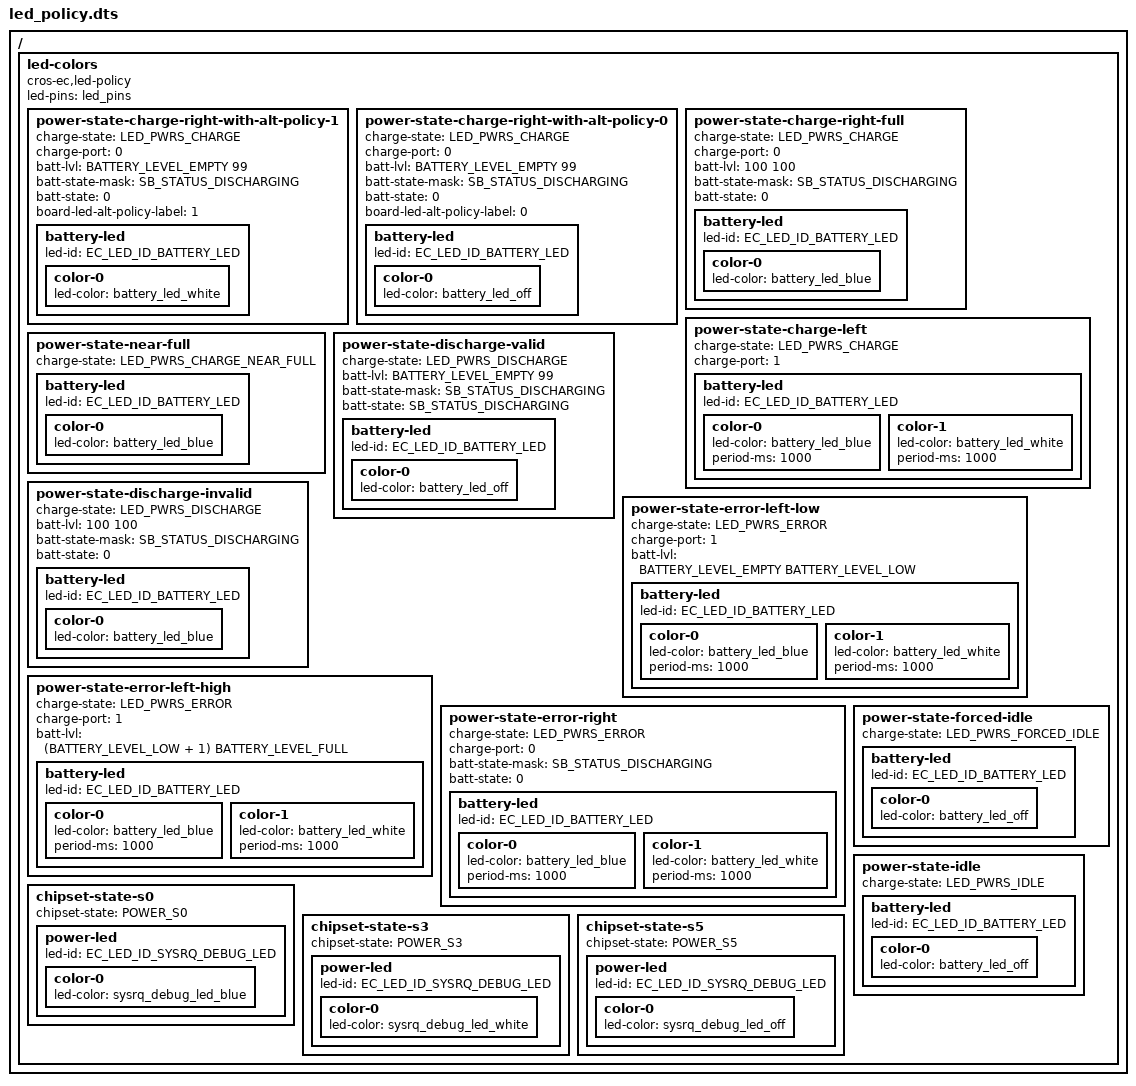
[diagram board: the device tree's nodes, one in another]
/* Copyright 2022 The ChromiumOS Authors
 * Use of this source code is governed by a BSD-style license that can be
 * found in the LICENSE file.
 */

/* Based off of `ec/zephyr/program/brox/led_policy.dtsi`
 * Modified led-colors to obtain better test coverage.
 */

#include <dt-bindings/battery.h>

/ {
	led-colors {
		compatible = "cros-ec,led-policy";
		led-pins = <&led_pins>;

		power-state-charge-right-with-alt-policy-1 {
			charge-state = "LED_PWRS_CHARGE";
			charge-port = <0>; /* Right port */
			batt-lvl = <BATTERY_LEVEL_EMPTY 99>;
			/* Battery is charging */
			batt-state-mask = <SB_STATUS_DISCHARGING>;
			batt-state = <0>;
			board-led-alt-policy-label = <1>;

			battery-led {
				led-id = "EC_LED_ID_BATTERY_LED";

				color-0 {
					led-color = <&battery_led_white>;
				};
			};
		};

		power-state-charge-right-with-alt-policy-0 {
			charge-state = "LED_PWRS_CHARGE";
			charge-port = <0>; /* Right port */
			batt-lvl = <BATTERY_LEVEL_EMPTY 99>;
			/* Battery is charging */
			batt-state-mask = <SB_STATUS_DISCHARGING>;
			batt-state = <0>;
			board-led-alt-policy-label = <0>;

			battery-led {
				led-id = "EC_LED_ID_BATTERY_LED";

				color-0 {
					led-color = <&battery_led_off>;
				};
			};
		};

		power-state-charge-right-full {
			charge-state = "LED_PWRS_CHARGE";
			charge-port = <0>; /* Right port */
			batt-lvl = <100 100>;
			/* Battery is charging */
			batt-state-mask = <SB_STATUS_DISCHARGING>;
			batt-state = <0>;

			battery-led {
				led-id = "EC_LED_ID_BATTERY_LED";

				color-0 {
					led-color = <&battery_led_blue>;
				};
			};
		};

		power-state-charge-left {
			charge-state = "LED_PWRS_CHARGE";
			charge-port = <1>; /* Left port */

			battery-led {
				led-id = "EC_LED_ID_BATTERY_LED";
				/* Blue 1 sec, White 1 sec */
				color-0 {
					led-color = <&battery_led_blue>;
					period-ms = <1000>;
				};
				color-1 {
					led-color = <&battery_led_white>;
					period-ms = <1000>;
				};
			};
		};

		power-state-near-full {
			charge-state = "LED_PWRS_CHARGE_NEAR_FULL";

			battery-led {
				led-id = "EC_LED_ID_BATTERY_LED";

				color-0 {
					led-color = <&battery_led_blue>;
				};
			};
		};

		power-state-discharge-valid {
			charge-state = "LED_PWRS_DISCHARGE";
			batt-lvl = <BATTERY_LEVEL_EMPTY 99>;
			/* Battery is discharging */
			batt-state-mask = <SB_STATUS_DISCHARGING>;
			batt-state = <SB_STATUS_DISCHARGING>;

			battery-led {
				led-id = "EC_LED_ID_BATTERY_LED";

				color-0 {
					led-color = <&battery_led_off>;
				};
			};
		};

		/* This policy is invalid and should never trigger*/
		power-state-discharge-invalid {
			charge-state = "LED_PWRS_DISCHARGE";
			batt-lvl = <100 100>;
			batt-state-mask = <SB_STATUS_DISCHARGING>;
			batt-state = <0>;

			battery-led {
				led-id = "EC_LED_ID_BATTERY_LED";

				color-0 {
					led-color = <&battery_led_blue>;
				};
			};
		};

		power-state-error-left-low {
			charge-state = "LED_PWRS_ERROR";
			charge-port = <1>; /* Left port */
			batt-lvl = <BATTERY_LEVEL_EMPTY BATTERY_LEVEL_LOW>;

			battery-led {
				led-id = "EC_LED_ID_BATTERY_LED";
				/* Blue 1 sec, White 1 sec */
				color-0 {
					led-color = <&battery_led_blue>;
					period-ms = <1000>;
				};
				color-1 {
					led-color = <&battery_led_white>;
					period-ms = <1000>;
				};
			};
		};

		power-state-error-left-high {
			charge-state = "LED_PWRS_ERROR";
			charge-port = <1>; /* Left port */
			batt-lvl = <(BATTERY_LEVEL_LOW + 1) BATTERY_LEVEL_FULL>;

			battery-led {
				led-id = "EC_LED_ID_BATTERY_LED";
				/* Blue 1 sec, White 1 sec */
				color-0 {
					led-color = <&battery_led_blue>;
					period-ms = <1000>;
				};
				color-1 {
					led-color = <&battery_led_white>;
					period-ms = <1000>;
				};
			};
		};

		power-state-error-right {
			charge-state = "LED_PWRS_ERROR";
			charge-port = <0>; /* Right port */
			/* Battery is charging */
			batt-state-mask = <SB_STATUS_DISCHARGING>;
			batt-state = <0>;

			battery-led {
				led-id = "EC_LED_ID_BATTERY_LED";
				/* Blue 1 sec, White 1 sec */
				color-0 {
					led-color = <&battery_led_blue>;
					period-ms = <1000>;
				};
				color-1 {
					led-color = <&battery_led_white>;
					period-ms = <1000>;
				};
			};
		};

		power-state-forced-idle {
			charge-state = "LED_PWRS_FORCED_IDLE";

			battery-led {
				led-id = "EC_LED_ID_BATTERY_LED";
				color-0 {
					led-color = <&battery_led_off>;
				};
			};
		};

		power-state-idle {
			charge-state = "LED_PWRS_IDLE";

			battery-led {
				led-id = "EC_LED_ID_BATTERY_LED";
				color-0 {
					led-color = <&battery_led_off>;
				};
			};
		};

		chipset-state-s0 {
			chipset-state = "POWER_S0";

			power-led {
				led-id = "EC_LED_ID_SYSRQ_DEBUG_LED";

				color-0 {
					led-color = <&sysrq_debug_led_blue>;
				};
			};
		};

		chipset-state-s3 {
			chipset-state = "POWER_S3";

			power-led {
				led-id = "EC_LED_ID_SYSRQ_DEBUG_LED";

				color-0 {
					led-color = <&sysrq_debug_led_white>;
				};
			};
		};

		chipset-state-s5 {
			chipset-state = "POWER_S5";

			power-led {
				led-id = "EC_LED_ID_SYSRQ_DEBUG_LED";

				color-0 {
					led-color = <&sysrq_debug_led_off>;
				};
			};
		};
	};
};
